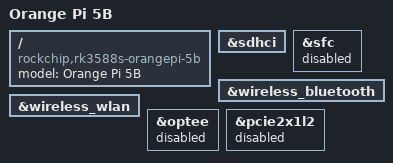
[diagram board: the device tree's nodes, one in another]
// SPDX-License-Identifier: (GPL-2.0+ OR MIT)
/*
 * Copyright (c) 2021 Rockchip Electronics Co., Ltd.
 *
 */

/dts-v1/;

#include "rk3588s-orangepi-5.dts"

/ {
	model = "Orange Pi 5B";
	compatible = "rockchip,rk3588s-orangepi-5b", "rockchip,rk3588s-orangepi-5", "rockchip,rk3588";
};

&sdhci {
	status = "okay";
};

&sfc {
	status = "disabled";
};

&wireless_bluetooth {
	status = "okay";
};

&wireless_wlan {
	status = "okay";
};


/*
 * Current OPi5B raw SD/eMMC boot chain does not provide a valid OP-TEE BL32.
 * Keep BL31/bootloader policy separate, but do not let Linux probe a stale
 * OP-TEE firmware node from rk3588-linux.dtsi.
 */
&optee {
	status = "disabled";
};


/*
 * fe190000 PCIe host reports invalid resources on OPi5B in current DT.
 * Keep the AP6275P Wi-Fi PCIe path enabled; disable only this broken host.
 */
&pcie2x1l2 {
	status = "disabled";
};
